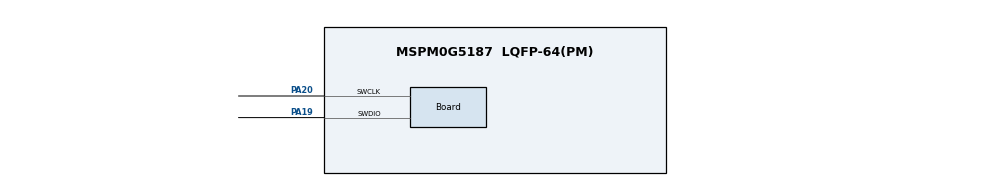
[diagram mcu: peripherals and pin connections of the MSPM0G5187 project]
//@cliArgs --device "MSPM0G518X" --package "LQFP-64(PM)" --part "Default"
//@v2CliArgs --device "MSPM0G5187" --package "LQFP-64(PM)"
// @cliArgs --board /ti/boards/LP_MSPM0G5187 --rtos nortos

/**
 * Import the modules used in this configuration.
 */
const AESADV = scripting.addModule("/ti/driverlib/AESADV");
const SYSCTL = scripting.addModule("/ti/driverlib/SYSCTL");

/**
 * Write custom configuration values to the imported modules.
 */
AESADV.lowerCryptoLength = 0x10;
AESADV.keySize           = "DL_AESADV_KEY_SIZE_256_BIT";

const Board                       = scripting.addModule("/ti/driverlib/Board", {}, false);
Board.peripheral.$assign          = "DEBUGSS";
Board.peripheral.swclkPin.$assign = "PA20";
Board.peripheral.swdioPin.$assign = "PA19";

SYSCTL.forceDefaultClkConfig = true;
SYSCTL.clockTreeEn           = true;

const ProjectConfig              = scripting.addModule("/ti/project_config/ProjectConfig", {}, false);
ProjectConfig.migrationCondition = true;
